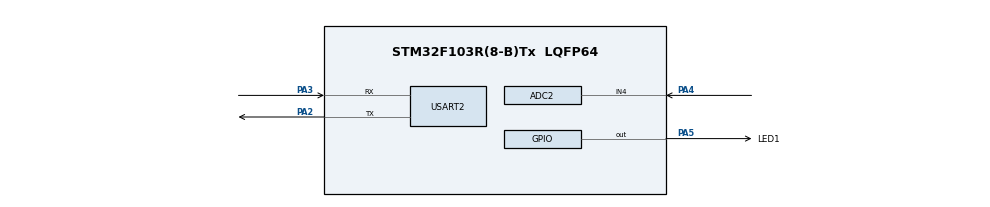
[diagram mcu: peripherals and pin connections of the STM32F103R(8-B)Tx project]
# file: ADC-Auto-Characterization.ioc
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ADC2.Channel-1\#ChannelRegularConversion=ADC_CHANNEL_4
ADC2.ContinuousConvMode=DISABLE
ADC2.NbrOfConversionFlag=1
ADC2.Rank-1\#ChannelRegularConversion=1
ADC2.SamplingTime-1\#ChannelRegularConversion=ADC_SAMPLETIME_1CYCLE_5
Mcu.Family=STM32F1
Mcu.Name=STM32F103R(8-B)Tx
Mcu.Package=LQFP64
NVIC.PriorityGroup=NVIC_PRIORITYGROUP_4
PA13.Mode=Serial_Wire
PA13.Signal=SYS_JTMS-SWDIO
PA14.Mode=Serial_Wire
PA14.Signal=SYS_JTCK-SWCLK
PA2.Mode=Asynchronous
PA2.Signal=USART2_TX
PA3.Mode=Asynchronous
PA3.Signal=USART2_RX
PA4.Signal=ADCx_IN4
PA5.GPIO_Label=LED1
PA5.Signal=GPIO_Output
ProjectManager.HeapSize=0x200
ProjectManager.StackSize=0x400
ProjectManager.TargetToolchain=STM32CubeIDE
RCC.APB1Freq_Value=8000000
RCC.APB2Freq_Value=8000000
SH.ADCx_IN4.0=ADC2_IN4,IN4
USART2.VirtualMode=VM_ASYNC
board=custom

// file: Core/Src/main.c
/* USER CODE BEGIN Header */
/**
  ******************************************************************************
  * @file           : main.c
  * @brief          : Main program body
  ******************************************************************************
  * @attention
  *
  * Copyright (c) 2024 STMicroelectronics.
  * All rights reserved.
  *
  * This software is licensed under terms that can be found in the LICENSE file
  * in the root directory of this software component.
  * If no LICENSE file comes with this software, it is provided AS-IS.
  *
  ******************************************************************************
  */
/* USER CODE END Header */
#include "main.h"

ADC_HandleTypeDef hadc2;

UART_HandleTypeDef huart2;

void SystemClock_Config(void);
static void MX_GPIO_Init(void);
static void MX_USART2_UART_Init(void);
static void MX_ADC2_Init(void);

int main(void)
{

  /* MCU Configuration--------------------------------------------------------*/

  /* Reset of all peripherals, Initializes the Flash interface and the Systick. */
  HAL_Init();

  /* Configure the system clock */
  SystemClock_Config();

  /* Initialize all configured peripherals */
  MX_GPIO_Init();
  MX_USART2_UART_Init();
  MX_ADC2_Init();

  /* Infinite loop */
  while (1)
  {

    /* USER CODE BEGIN 3 */

    // This function waits until 's' is received on UART to continue
    // This way, from the Python script we can command the STM32 chip operate only when we tell it to
    Continue_On_UART_Receive(huart2);

	  HAL_GPIO_TogglePin(LED1_GPIO_Port, LED1_Pin); // Toggle the LED high when we're collecting or sending values

    int adcValuesAveraged = 0;
    int adcValuesAdjusted = 0;
    Get_Averaged_ADC_Values(hadc2, 50, 1, &adcValuesAveraged, &adcValuesAdjusted);

    Send_ADC_Values_Over_UART(huart2, adcValuesAveraged, adcValuesAdjusted);

	  HAL_GPIO_TogglePin(LED1_GPIO_Port, LED1_Pin);
  }
  /* USER CODE END 3 */
}

void SystemClock_Config(void)
{
  RCC_OscInitTypeDef RCC_OscInitStruct = {0};
  RCC_ClkInitTypeDef RCC_ClkInitStruct = {0};
  RCC_PeriphCLKInitTypeDef PeriphClkInit = {0};

  /** Initializes the RCC Oscillators according to the specified parameters
  * in the RCC_OscInitTypeDef structure.
  */
  RCC_OscInitStruct.OscillatorType = RCC_OSCILLATORTYPE_HSI;
  RCC_OscInitStruct.HSIState = RCC_HSI_ON;
  RCC_OscInitStruct.HSICalibrationValue = RCC_HSICALIBRATION_DEFAULT;
  RCC_OscInitStruct.PLL.PLLState = RCC_PLL_NONE;
  if (HAL_RCC_OscConfig(&RCC_OscInitStruct) != HAL_OK)
  {
    Error_Handler();
  }

  /** Initializes the CPU, AHB and APB buses clocks
  */
  RCC_ClkInitStruct.ClockType = RCC_CLOCKTYPE_HCLK|RCC_CLOCKTYPE_SYSCLK
                              |RCC_CLOCKTYPE_PCLK1|RCC_CLOCKTYPE_PCLK2;
  RCC_ClkInitStruct.SYSCLKSource = RCC_SYSCLKSOURCE_HSI;
  RCC_ClkInitStruct.AHBCLKDivider = RCC_SYSCLK_DIV1;
  RCC_ClkInitStruct.APB1CLKDivider = RCC_HCLK_DIV1;
  RCC_ClkInitStruct.APB2CLKDivider = RCC_HCLK_DIV1;

  if (HAL_RCC_ClockConfig(&RCC_ClkInitStruct, FLASH_LATENCY_0) != HAL_OK)
  {
    Error_Handler();
  }
  PeriphClkInit.PeriphClockSelection = RCC_PERIPHCLK_ADC;
  PeriphClkInit.AdcClockSelection = RCC_ADCPCLK2_DIV2;
  if (HAL_RCCEx_PeriphCLKConfig(&PeriphClkInit) != HAL_OK)
  {
    Error_Handler();
  }
}

static void MX_ADC2_Init(void)
{

  ADC_ChannelConfTypeDef sConfig = {0};

  /** Common config
  */
  hadc2.Instance = ADC2;
  hadc2.Init.ScanConvMode = ADC_SCAN_DISABLE;
  hadc2.Init.ContinuousConvMode = DISABLE;
  hadc2.Init.DiscontinuousConvMode = DISABLE;
  hadc2.Init.ExternalTrigConv = ADC_SOFTWARE_START;
  hadc2.Init.DataAlign = ADC_DATAALIGN_RIGHT;
  hadc2.Init.NbrOfConversion = 1;
  if (HAL_ADC_Init(&hadc2) != HAL_OK)
  {
    Error_Handler();
  }

  /** Configure Regular Channel
  */
  sConfig.Channel = ADC_CHANNEL_4;
  sConfig.Rank = ADC_REGULAR_RANK_1;
  sConfig.SamplingTime = ADC_SAMPLETIME_1CYCLE_5;
  if (HAL_ADC_ConfigChannel(&hadc2, &sConfig) != HAL_OK)
  {
    Error_Handler();
  }

}

static void MX_USART2_UART_Init(void)
{

  huart2.Instance = USART2;
  huart2.Init.BaudRate = 115200;
  huart2.Init.WordLength = UART_WORDLENGTH_8B;
  huart2.Init.StopBits = UART_STOPBITS_1;
  huart2.Init.Parity = UART_PARITY_NONE;
  huart2.Init.Mode = UART_MODE_TX_RX;
  huart2.Init.HwFlowCtl = UART_HWCONTROL_NONE;
  huart2.Init.OverSampling = UART_OVERSAMPLING_16;
  if (HAL_UART_Init(&huart2) != HAL_OK)
  {
    Error_Handler();
  }

}

static void MX_GPIO_Init(void)
{
  GPIO_InitTypeDef GPIO_InitStruct = {0};

  /* GPIO Ports Clock Enable */
  __HAL_RCC_GPIOA_CLK_ENABLE();

  /*Configure GPIO pin Output Level */
  HAL_GPIO_WritePin(LED1_GPIO_Port, LED1_Pin, GPIO_PIN_RESET);

  /*Configure GPIO pin : LED1_Pin */
  GPIO_InitStruct.Pin = LED1_Pin;
  GPIO_InitStruct.Mode = GPIO_MODE_OUTPUT_PP;
  GPIO_InitStruct.Pull = GPIO_NOPULL;
  GPIO_InitStruct.Speed = GPIO_SPEED_FREQ_LOW;
  HAL_GPIO_Init(LED1_GPIO_Port, &GPIO_InitStruct);

}

void Error_Handler(void)
{
  __disable_irq();
  while (1)
  {
  }
}
